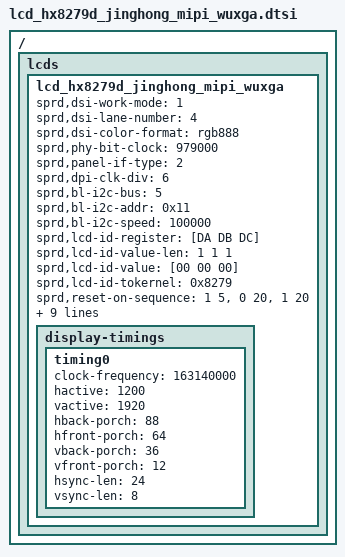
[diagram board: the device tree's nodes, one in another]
/*
* hx8279d jinghong LCD config dtsi file for spreadtrum
*
* Copyright (C) 2021, Spreadtrum Communications Inc.
*
* SPDX-License-Identifier: (GPL-2.0+ OR MIT)
*/

/ { lcds {
  lcd_hx8279d_jinghong_mipi_wuxga: lcd_hx8279d_jinghong_mipi_wuxga {

	  sprd,dsi-work-mode = <1>;
	  sprd,dsi-lane-number = <4>;
	  sprd,dsi-color-format = "rgb888";

	  sprd,phy-bit-clock = <979000>;

          /* panel interface type: 2:MIPI; 3:SPI */
	  sprd,panel-if-type = <2>;
	  sprd,dpi-clk-div = <6>;

	  /*---Panel Backlight---*/
	  sprd,bl-i2c-bus = <5>;
	  sprd,bl-i2c-addr = <0x11>;
	  sprd,bl-i2c-speed = <100000>;

	  /*----Id register ----*/
	  sprd,lcd-id-register = [DA DB DC];
	  sprd,lcd-id-value-len = <1 1 1>;
	  sprd,lcd-id-value = [00 00 00];
	  sprd,lcd-id-tokernel = <0x8279>;

	  sprd,reset-on-sequence = <1 5>, <0 20>, <1 20>;
	  sprd,reset-off-sequence = <0 20>;
	  sprd,video-lp-cmd-enable = <1>;
	  sprd,hporch-lp-disable = <1>;
	  sprd,initial-command = [
		  15 00 00 02 B0 01
		  15 00 00 02 C3 4F
		  15 00 00 02 C4 40
		  15 00 00 02 C5 40
		  15 00 00 02 C6 40
		  15 00 00 02 C7 40
		  15 00 00 02 C8 4D
		  15 00 00 02 C9 52
		  15 00 00 02 CA 51
		  15 00 00 02 CD 5D
		  15 00 00 02 CE 5B
		  15 00 00 02 CF 4B
		  15 00 00 02 D0 49
		  15 00 00 02 D1 47
		  15 00 00 02 D2 45
		  15 00 00 02 D3 41
		  15 00 00 02 D7 50
		  15 00 00 02 D8 40
		  15 00 00 02 D9 40
		  15 00 00 02 DA 40
		  15 00 00 02 DB 40
		  15 00 00 02 DC 4E
		  15 00 00 02 DD 52
		  15 00 00 02 DE 51
		  15 00 00 02 E1 5E
		  15 00 00 02 E2 5C
		  15 00 00 02 E3 4C
		  15 00 00 02 E4 4A
		  15 00 00 02 E5 48
		  15 00 00 02 E6 46
		  15 00 00 02 E7 42
		  15 00 00 02 B0 03
		  15 00 00 02 BE 03
		  15 00 00 02 CC 44
		  15 00 00 02 C8 07
		  15 00 00 02 C9 05
		  15 00 00 02 CA 42
		  15 00 00 02 CD 3E
		  15 00 00 02 CF 60
		  15 00 00 02 D2 04
		  15 00 00 02 D3 04
		  15 00 00 02 D4 01
		  15 00 00 02 D5 00
		  15 00 00 02 D6 03
		  15 00 00 02 D7 04
		  15 00 00 02 D9 01
		  15 00 00 02 DB 01
		  15 00 00 02 E4 F0
		  15 00 00 02 E5 0A
		  15 00 00 02 B0 00
		  15 00 00 02 BD 63
		  15 00 00 02 C2 08
		  15 00 00 02 C4 10
		  15 00 00 02 B0 02
		  15 00 00 02 C0 00
		  15 00 00 02 C1 0A
		  15 00 00 02 C2 20
		  15 00 00 02 C3 24
		  15 00 00 02 C4 23
		  15 00 00 02 C5 29
		  15 00 00 02 C6 23
		  15 00 00 02 C7 1C
		  15 00 00 02 C8 19
		  15 00 00 02 C9 17
		  15 00 00 02 CA 17
		  15 00 00 02 CB 18
		  15 00 00 02 CC 1A
		  15 00 00 02 CD 1E
		  15 00 00 02 CE 20
		  15 00 00 02 CF 23
		  15 00 00 02 D0 07
		  15 00 00 02 D1 00
		  15 00 00 02 D2 00
		  15 00 00 02 D3 0A
		  15 00 00 02 D4 13
		  15 00 00 02 D5 1C
		  15 00 00 02 D6 1A
		  15 00 00 02 D7 13
		  15 00 00 02 D8 17
		  15 00 00 02 D9 1C
		  15 00 00 02 DA 19
		  15 00 00 02 DB 17
		  15 00 00 02 DC 17
		  15 00 00 02 DD 18
		  15 00 00 02 DE 1A
		  15 00 00 02 DF 1E
		  15 00 00 02 E0 20
		  15 00 00 02 E1 23
		  15 00 00 02 E2 07
		  05 78 00 02 11 00
		  05 32 00 02 29 00
	  ];

	  sprd,sleep-in-command = [
		  13 0A 00 01 28
		  13 78 00 01 10
		  ];
	  sprd,sleep-out-command = [
		  13 78 00 01 11
		  13 64 00 01 29
		  ];

	  display-timings {
		  timing0 {
			  clock-frequency = <163140000>;
			  hactive = <1200>;
			  vactive = <1920>;
			  hback-porch = <88>;
			  hfront-porch = <64>;
			  vback-porch = <36>;
			  vfront-porch = <12>;
			  hsync-len = <24>;
			  vsync-len = <8>;

		  };
	  };
  };
};};
